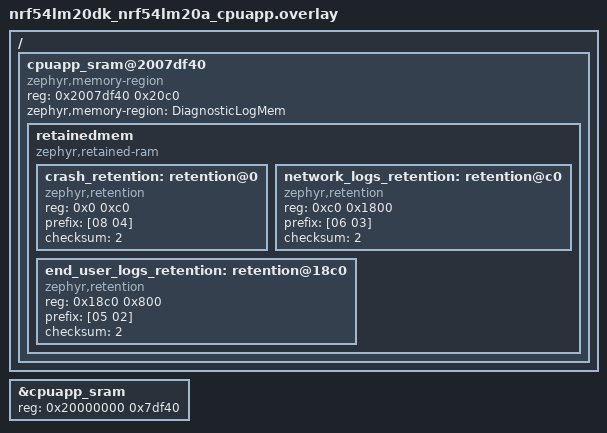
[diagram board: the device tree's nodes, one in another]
/* Copyright (c) 2025 Nordic Semiconductor ASA
 *
 * SPDX-License-Identifier: LicenseRef-Nordic-5-Clause
 */

/ {
	cpuapp_sram@2007df40 {
		compatible = "zephyr,memory-region", "mmio-sram";
		reg = <0x2007df40 0x20c0>;
		zephyr,memory-region = "DiagnosticLogMem";
		status = "okay";

		retainedmem {
			compatible = "zephyr,retained-ram";
			status = "okay";
			#address-cells = <1>;
			#size-cells = <1>;

			/* Reserve 192 B for the crash logs. */
			crash_retention: retention@0 {
				compatible = "zephyr,retention";
				status = "okay";
				reg = <0x0 0xc0>;
				prefix = [08 04];
				checksum = <2>;
			};

			/* Reserve 6 kB for the network logs. */
			network_logs_retention: retention@c0 {
				compatible = "zephyr,retention";
				status = "okay";
				reg = <0xc0 0x1800>;
				prefix = [06 03];
				checksum = <2>;
			};

			/* Reserve 2 kB for the end user logs. */
			end_user_logs_retention: retention@18c0 {
				compatible = "zephyr,retention";
				status = "okay";
				reg = <0x18c0 0x800>;
				prefix = [05 02];
				checksum = <2>;
			};
		};
	};
};

/* Reduce cpuapp_sram usage by 8384 B to account for non-init area */
&cpuapp_sram {
	reg = <0x20000000 0x7df40>;
};
